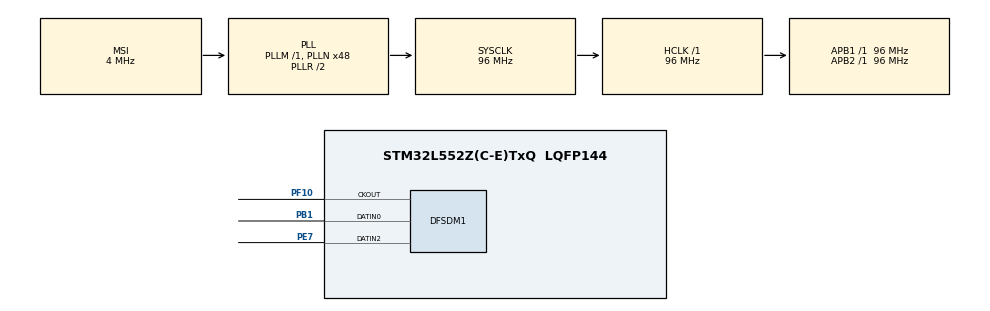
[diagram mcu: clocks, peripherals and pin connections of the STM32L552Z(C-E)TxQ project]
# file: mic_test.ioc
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DFSDM1.Divider=40
DFSDM1.DmaMode_reg_FIL0=ENABLE
DFSDM1.DmaMode_reg_FIL1=ENABLE
DFSDM1.DmaMode_reg_FIL2=ENABLE
DFSDM1.DmaMode_reg_FIL3=ENABLE
DFSDM1.FastMode_reg_FIL0=ENABLE
DFSDM1.FastMode_reg_FIL1=ENABLE
DFSDM1.FastMode_reg_FIL2=ENABLE
DFSDM1.FastMode_reg_FIL3=ENABLE
DFSDM1.Filter_regChannel_FIL0=DFSDM_CHANNEL_2
DFSDM1.Filter_regChannel_FIL1=DFSDM_CHANNEL_1
DFSDM1.Filter_regChannel_FIL2=DFSDM_CHANNEL_0
DFSDM1.Filter_regChannel_FIL3=DFSDM_CHANNEL_3
DFSDM1.Fosr_FIL0=150
DFSDM1.Fosr_FIL1=150
DFSDM1.Fosr_FIL2=150
DFSDM1.Fosr_FIL3=150
DFSDM1.RightBitShift_CH0=0x07
DFSDM1.RightBitShift_CH1=0x07
DFSDM1.RightBitShift_CH2=0x07
DFSDM1.RightBitShift_CH3=0x07
DFSDM1.SincOrder_FIL0=DFSDM_FILTER_SINC3_ORDER
DFSDM1.SincOrder_FIL1=DFSDM_FILTER_SINC3_ORDER
DFSDM1.SincOrder_FIL2=DFSDM_FILTER_SINC3_ORDER
DFSDM1.SincOrder_FIL3=DFSDM_FILTER_SINC3_ORDER
DFSDM1.Trigger_reg_FIL1=DFSDM_FILTER_SW_TRIGGER
DFSDM1.Trigger_reg_FIL2=DFSDM_FILTER_SW_TRIGGER
DFSDM1.Type_spi_CH1=DFSDM_CHANNEL_SPI_FALLING
DFSDM1.Type_spi_CH3=DFSDM_CHANNEL_SPI_FALLING
Dma.DFSDM1_FLT0.0.Channel_PRIV_NPRIV=DMA_CHANNEL_NPRIV_DISABLE
Dma.DFSDM1_FLT0.0.Direction=DMA_PERIPH_TO_MEMORY
Dma.DFSDM1_FLT0.0.EventEnable=DISABLE
Dma.DFSDM1_FLT0.0.Instance=DMA1_Channel1
Dma.DFSDM1_FLT0.0.MemDataAlignment=DMA_MDATAALIGN_WORD
Dma.DFSDM1_FLT0.0.MemInc=DMA_MINC_ENABLE
Dma.DFSDM1_FLT0.0.Mode=DMA_CIRCULAR
Dma.DFSDM1_FLT0.0.PeriphDataAlignment=DMA_PDATAALIGN_WORD
Dma.DFSDM1_FLT0.0.PeriphInc=DMA_PINC_DISABLE
Dma.DFSDM1_FLT0.0.Polarity=HAL_DMAMUX_REQ_GEN_RISING
Dma.DFSDM1_FLT0.0.Priority=DMA_PRIORITY_LOW
Dma.DFSDM1_FLT0.0.RequestNumber=1
Dma.DFSDM1_FLT0.0.SignalID=NONE
Dma.DFSDM1_FLT0.0.SyncEnable=DISABLE
Dma.DFSDM1_FLT0.0.SyncPolarity=HAL_DMAMUX_SYNC_NO_EVENT
Dma.DFSDM1_FLT0.0.SyncRequestNumber=1
Dma.DFSDM1_FLT0.0.SyncSignalID=NONE
Dma.DFSDM1_FLT1.1.Channel_PRIV_NPRIV=DMA_CHANNEL_NPRIV_DISABLE
Dma.DFSDM1_FLT1.1.Direction=DMA_PERIPH_TO_MEMORY
Dma.DFSDM1_FLT1.1.EventEnable=DISABLE
Dma.DFSDM1_FLT1.1.Instance=DMA1_Channel2
Dma.DFSDM1_FLT1.1.MemDataAlignment=DMA_MDATAALIGN_WORD
Dma.DFSDM1_FLT1.1.MemInc=DMA_MINC_ENABLE
Dma.DFSDM1_FLT1.1.Mode=DMA_CIRCULAR
Dma.DFSDM1_FLT1.1.PeriphDataAlignment=DMA_PDATAALIGN_WORD
Dma.DFSDM1_FLT1.1.PeriphInc=DMA_PINC_DISABLE
Dma.DFSDM1_FLT1.1.Polarity=HAL_DMAMUX_REQ_GEN_RISING
Dma.DFSDM1_FLT1.1.Priority=DMA_PRIORITY_LOW
Dma.DFSDM1_FLT1.1.RequestNumber=1
Dma.DFSDM1_FLT1.1.SignalID=NONE
Dma.DFSDM1_FLT1.1.SyncEnable=DISABLE
Dma.DFSDM1_FLT1.1.SyncPolarity=HAL_DMAMUX_SYNC_NO_EVENT
Dma.DFSDM1_FLT1.1.SyncRequestNumber=1
Dma.DFSDM1_FLT1.1.SyncSignalID=NONE
Dma.DFSDM1_FLT2.3.Channel_PRIV_NPRIV=DMA_CHANNEL_NPRIV_DISABLE
Dma.DFSDM1_FLT2.3.Direction=DMA_PERIPH_TO_MEMORY
Dma.DFSDM1_FLT2.3.EventEnable=DISABLE
Dma.DFSDM1_FLT2.3.Instance=DMA1_Channel4
Dma.DFSDM1_FLT2.3.MemDataAlignment=DMA_MDATAALIGN_WORD
Dma.DFSDM1_FLT2.3.MemInc=DMA_MINC_ENABLE
Dma.DFSDM1_FLT2.3.Mode=DMA_CIRCULAR
Dma.DFSDM1_FLT2.3.PeriphDataAlignment=DMA_PDATAALIGN_WORD
Dma.DFSDM1_FLT2.3.PeriphInc=DMA_PINC_DISABLE
Dma.DFSDM1_FLT2.3.Polarity=HAL_DMAMUX_REQ_GEN_RISING
Dma.DFSDM1_FLT2.3.Priority=DMA_PRIORITY_LOW
Dma.DFSDM1_FLT2.3.RequestNumber=1
Dma.DFSDM1_FLT2.3.SignalID=NONE
Dma.DFSDM1_FLT2.3.SyncEnable=DISABLE
Dma.DFSDM1_FLT2.3.SyncPolarity=HAL_DMAMUX_SYNC_NO_EVENT
Dma.DFSDM1_FLT2.3.SyncRequestNumber=1
Dma.DFSDM1_FLT2.3.SyncSignalID=NONE
Dma.DFSDM1_FLT3.2.Channel_PRIV_NPRIV=DMA_CHANNEL_NPRIV_DISABLE
Dma.DFSDM1_FLT3.2.Direction=DMA_PERIPH_TO_MEMORY
Dma.DFSDM1_FLT3.2.EventEnable=DISABLE
Dma.DFSDM1_FLT3.2.Instance=DMA1_Channel3
Dma.DFSDM1_FLT3.2.MemDataAlignment=DMA_MDATAALIGN_WORD
Dma.DFSDM1_FLT3.2.MemInc=DMA_MINC_ENABLE
Dma.DFSDM1_FLT3.2.Mode=DMA_CIRCULAR
Dma.DFSDM1_FLT3.2.PeriphDataAlignment=DMA_PDATAALIGN_WORD
Dma.DFSDM1_FLT3.2.PeriphInc=DMA_PINC_DISABLE
Dma.DFSDM1_FLT3.2.Polarity=HAL_DMAMUX_REQ_GEN_RISING
Dma.DFSDM1_FLT3.2.Priority=DMA_PRIORITY_LOW
Dma.DFSDM1_FLT3.2.RequestNumber=1
Dma.DFSDM1_FLT3.2.SignalID=NONE
Dma.DFSDM1_FLT3.2.SyncEnable=DISABLE
Dma.DFSDM1_FLT3.2.SyncPolarity=HAL_DMAMUX_SYNC_NO_EVENT
Dma.DFSDM1_FLT3.2.SyncRequestNumber=1
Dma.DFSDM1_FLT3.2.SyncSignalID=NONE
Dma.Request0=DFSDM1_FLT0
Dma.Request1=DFSDM1_FLT1
Dma.Request2=DFSDM1_FLT3
Dma.Request3=DFSDM1_FLT2
Mcu.Family=STM32L5
Mcu.Name=STM32L552Z(C-E)TxQ
Mcu.Package=LQFP144
Mcu.TrustZone=disable
NUCLEO-L552ZE-Q.BUTTON=1
NUCLEO-L552ZE-Q.Bsp_Common_DEMO=true
NUCLEO-L552ZE-Q.LD1=true
NUCLEO-L552ZE-Q.LD2=true
NUCLEO-L552ZE-Q.LD3=true
NUCLEO-L552ZE-Q.VCP=true
NVIC.DMA1_Channel1_IRQn=true\:0\:0\:false\:false\:true\:false\:true\:true
NVIC.DMA1_Channel2_IRQn=true\:0\:0\:false\:false\:true\:false\:true\:true
NVIC.DMA1_Channel3_IRQn=true\:0\:0\:false\:false\:true\:false\:true\:true
NVIC.DMA1_Channel4_IRQn=true\:0\:0\:false\:false\:true\:false\:true\:true
NVIC.EXTI13_IRQn=true\:0\:0\:false\:false\:true\:false\:true\:true
NVIC.PriorityGroup=NVIC_PRIORITYGROUP_3
PA13\ (JTMS/SWDIO).Signal=DEBUG_JTMS-SWDIO
PA14\ (JTCK/SWCLK).Signal=DEBUG_JTCK-SWCLK
PB1.Signal=S_DATAIN0DFSDM1
PB3\ (JTDO/TRACESWO).Signal=DEBUG_JTDO-SWO
PC14-OSC32_IN\ (PC14).Signal=RCC_OSC32_IN
PC15-OSC32_OUT\ (PC15).Signal=RCC_OSC32_OUT
PE7.Signal=S_DATAIN2DFSDM1
PF10.Signal=S_CKOUTDFSDM1
PG7.Signal=LPUART1_TX
PG8.Signal=LPUART1_RX
ProjectManager.HeapSize=0x200
ProjectManager.StackSize=0x400
ProjectManager.TargetToolchain=STM32CubeIDE
RCC.ADCCLockSelection=RCC_ADCCLKSOURCE_SYSCLK
RCC.ADCFreq_Value=96000000
RCC.AHBFreq_Value=96000000
RCC.APB1Freq_Value=96000000
RCC.APB1TimFreq_Value=96000000
RCC.APB2Freq_Value=96000000
RCC.APB2TimFreq_Value=96000000
RCC.CK48CLockSelection=RCC_USBCLKSOURCE_HSI48
RCC.CortexFreq_Value=96000000
RCC.HCLKFreq_Value=96000000
RCC.HSE_VALUE=8000000
RCC.HSI48_VALUE=48000000
RCC.HSI_VALUE=16000000
RCC.LSE_VALUE=32768
RCC.MSI_VALUE=4000000
RCC.PLLN=48
RCC.PLLSAI1N=24
RCC.RTCClockSelection=RCC_RTCCLKSOURCE_LSE
RCC.SYSCLKFreq_VALUE=96000000
RCC.SYSCLKSource=RCC_SYSCLKSOURCE_PLLCLK
RCC.USBFreq_Value=48000000
RCC.VCOOutputFreq_Value=192000000
SH.S_CKOUTDFSDM1.0=DFSDM1_CKOUT,PDM_SPI_input_from_ch2_and_internal_clock
SH.S_CKOUTDFSDM1.1=DFSDM1_CKOUT,PDM_SPI_Input_from_ch12_and_Internal_Clock
SH.S_CKOUTDFSDM1.2=DFSDM1_CKOUT,PDM_SPI_input_from_ch0_and_internal_clock
SH.S_CKOUTDFSDM1.3=DFSDM1_CKOUT,PDM_SPI_Input_from_ch30_and_Internal_Clock
SH.S_DATAIN0DFSDM1.0=DFSDM1_DATIN0,PDM_SPI_input_from_ch0_and_internal_clock
SH.S_DATAIN0DFSDM1.1=DFSDM1_DATIN0,PDM_SPI_Input_from_ch30_and_Internal_Clock
SH.S_DATAIN2DFSDM1.0=DFSDM1_DATIN2,PDM_SPI_input_from_ch2_and_internal_clock
SH.S_DATAIN2DFSDM1.1=DFSDM1_DATIN2,PDM_SPI_Input_from_ch12_and_Internal_Clock
VP_ICACHE_VS_ICACHE.Mode=DirectMappedCache
VP_NUCLEO-L552ZE-Q_VS_BSP_COMMON.Mode=COMMON
VP_PWR_VS_DBSignals.Mode=DisableDeadBatterySignals
VP_PWR_VS_SECSignals.Mode=Security/Privilege
board=NUCLEO-L552ZE-Q

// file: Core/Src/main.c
/* USER CODE BEGIN Header */
/**
  ******************************************************************************
  * @file           : main.c
  * @brief          : Main program body
  ******************************************************************************
  * @attention
  *
  * Copyright (c) 2026 STMicroelectronics.
  * All rights reserved.
  *
  * This software is licensed under terms that can be found in the LICENSE file
  * in the root directory of this software component.
  * If no LICENSE file comes with this software, it is provided AS-IS.
  *
  ******************************************************************************
  */
/* USER CODE END Header */
#include "main.h"

/* USER CODE BEGIN Includes */
#include "capture.h"
#include "localize.h"
/* USER CODE END Includes */

/* USER CODE BEGIN PD */
/* Capture configuration and buffers now live in capture.c / capture.h. */
/* USER CODE END PD */

COM_InitTypeDef BspCOMInit;
__IO uint32_t BspButtonState = BUTTON_RELEASED;
DFSDM_Filter_HandleTypeDef hdfsdm1_filter0;
DFSDM_Filter_HandleTypeDef hdfsdm1_filter1;
DFSDM_Filter_HandleTypeDef hdfsdm1_filter2;
DFSDM_Filter_HandleTypeDef hdfsdm1_filter3;
DFSDM_Channel_HandleTypeDef hdfsdm1_channel0;
DFSDM_Channel_HandleTypeDef hdfsdm1_channel1;
DFSDM_Channel_HandleTypeDef hdfsdm1_channel2;
DFSDM_Channel_HandleTypeDef hdfsdm1_channel3;
DMA_HandleTypeDef hdma_dfsdm1_flt0;
DMA_HandleTypeDef hdma_dfsdm1_flt1;
DMA_HandleTypeDef hdma_dfsdm1_flt3;
DMA_HandleTypeDef hdma_dfsdm1_flt2;

/* USER CODE BEGIN PV */
/* Capture buffers and state now live in capture.c (file-private). */
/* USER CODE END PV */

void SystemClock_Config(void);
static void MX_GPIO_Init(void);
static void MX_DMA_Init(void);
static void MX_ICACHE_Init(void);
static void MX_DFSDM1_Init(void);

/* USER CODE BEGIN 0 */
/* Capture helpers, DMA callbacks, and state machine now live in capture.c. */
/* USER CODE END 0 */

int main(void)
{

  /* MCU Configuration--------------------------------------------------------*/

  /* Reset of all peripherals, Initializes the Flash interface and the Systick. */
  HAL_Init();

  /* Configure the system clock */
  SystemClock_Config();

  /* Initialize all configured peripherals */
  MX_GPIO_Init();
  MX_DMA_Init();
  MX_ICACHE_Init();
  MX_DFSDM1_Init();
  /* USER CODE BEGIN 2 */

  /* Force filters 1-3 onto the sync trigger so they start in lockstep when
     filter0 starts. CubeMX generates SW_TRIGGER for all four; re-init the
     three slaves here so this holds even after a future regeneration. */
  hdfsdm1_filter1.Init.RegularParam.Trigger = DFSDM_FILTER_SYNC_TRIGGER;
  hdfsdm1_filter2.Init.RegularParam.Trigger = DFSDM_FILTER_SYNC_TRIGGER;
  hdfsdm1_filter3.Init.RegularParam.Trigger = DFSDM_FILTER_SYNC_TRIGGER;
  if (HAL_DFSDM_FilterInit(&hdfsdm1_filter1) != HAL_OK) Error_Handler();
  if (HAL_DFSDM_FilterInit(&hdfsdm1_filter2) != HAL_OK) Error_Handler();
  if (HAL_DFSDM_FilterInit(&hdfsdm1_filter3) != HAL_OK) Error_Handler();

  /* USER CODE END 2 */

  /* Initialize leds */
  BSP_LED_Init(LED_GREEN);
  BSP_LED_Init(LED_BLUE);
  BSP_LED_Init(LED_RED);

  /* Initialize USER push-button, will be used to trigger an interrupt each time it's pressed.*/
  BSP_PB_Init(BUTTON_USER, BUTTON_MODE_EXTI);

  /* Initialize COM1 port (115200, 8 bits (7-bit data + 1 stop bit), no parity */
  BspCOMInit.BaudRate   = 115200;
  BspCOMInit.WordLength = COM_WORDLENGTH_8B;
  BspCOMInit.StopBits   = COM_STOPBITS_1;
  BspCOMInit.Parity     = COM_PARITY_NONE;
  BspCOMInit.HwFlowCtl  = COM_HWCONTROL_NONE;
  if (BSP_COM_Init(COM1, &BspCOMInit) != BSP_ERROR_NONE)
  {
    Error_Handler();
  }

  /* USER CODE BEGIN BSP */

  /* -- Sample board code to send message over COM1 port ---- */
  printf("Welcome to STM32 world !\n\r");

  /* Prepare the on-board localizer: sets up the FFT and validates the active
     array geometry. Done once here rather than lazily on the first capture so
     a bad configuration is reported at boot, not eleven seconds after a clap. */
  if (!Localize_Init())
  {
    printf("WARNING: localizer failed to initialise. Captures will still be "
           "dumped, but no bearing will be computed.\r\n");
  }

  /* USER CODE END BSP */

  /* Infinite loop */
  /* USER CODE BEGIN WHILE */
  while (1)
  {
    /* IDLE: watch for the button. BspButtonState is set to BUTTON_PRESSED by
       the button's own interrupt (EXTI13 -> BSP_PB_Callback). A press arms a
       capture; Capture_Arm ignores it if one is already running. */
    if (BspButtonState == BUTTON_PRESSED)
    {
      BspButtonState = BUTTON_RELEASED;   /* consume the press so it fires once */
      Capture_Arm();
    }

    /* Run the capture state machine: drain the DMA frames, watch for the
       clap, and once a full second is banked, dump it over UART. Does
       nothing until armed. See capture.c. */
    Capture_Poll();

    /* A capture just finished and its raw audio is already on the wire.
       Localize it and print the bearing after the dump, so catch_audio4.py
       gets a clean WAV4 payload and the report lands in the terminal behind
       it. Takes a few tens of milliseconds; nothing else is time critical
       here because the array is idle until the next button press. */
    if (Capture_TakeResult())
    {
      static const int16_t *chans[4];
      for (int m = 0; m < 4; m++) chans[m] = Capture_Channel(m);

      static loc_result_t result;
      Localize_Run(chans, Capture_Length(), &result);
      Localize_Report(&result);
    }
    /* USER CODE END WHILE */

  }
}

void SystemClock_Config(void)
{
  RCC_OscInitTypeDef RCC_OscInitStruct = {0};
  RCC_ClkInitTypeDef RCC_ClkInitStruct = {0};

  /** Configure the main internal regulator output voltage
  */
  if (HAL_PWREx_ControlVoltageScaling(PWR_REGULATOR_VOLTAGE_SCALE0) != HAL_OK)
  {
    Error_Handler();
  }

  /** Initializes the RCC Oscillators according to the specified parameters
  * in the RCC_OscInitTypeDef structure.
  */
  RCC_OscInitStruct.OscillatorType = RCC_OSCILLATORTYPE_MSI;
  RCC_OscInitStruct.MSIState = RCC_MSI_ON;
  RCC_OscInitStruct.MSICalibrationValue = RCC_MSICALIBRATION_DEFAULT;
  RCC_OscInitStruct.MSIClockRange = RCC_MSIRANGE_6;
  RCC_OscInitStruct.PLL.PLLState = RCC_PLL_ON;
  RCC_OscInitStruct.PLL.PLLSource = RCC_PLLSOURCE_MSI;
  RCC_OscInitStruct.PLL.PLLM = 1;
  RCC_OscInitStruct.PLL.PLLN = 48;
  RCC_OscInitStruct.PLL.PLLP = RCC_PLLP_DIV7;
  RCC_OscInitStruct.PLL.PLLQ = RCC_PLLQ_DIV2;
  RCC_OscInitStruct.PLL.PLLR = RCC_PLLR_DIV2;
  if (HAL_RCC_OscConfig(&RCC_OscInitStruct) != HAL_OK)
  {
    Error_Handler();
  }

  /** Initializes the CPU, AHB and APB buses clocks
  */
  RCC_ClkInitStruct.ClockType = RCC_CLOCKTYPE_HCLK|RCC_CLOCKTYPE_SYSCLK
                              |RCC_CLOCKTYPE_PCLK1|RCC_CLOCKTYPE_PCLK2;
  RCC_ClkInitStruct.SYSCLKSource = RCC_SYSCLKSOURCE_PLLCLK;
  RCC_ClkInitStruct.AHBCLKDivider = RCC_SYSCLK_DIV1;
  RCC_ClkInitStruct.APB1CLKDivider = RCC_HCLK_DIV1;
  RCC_ClkInitStruct.APB2CLKDivider = RCC_HCLK_DIV1;

  if (HAL_RCC_ClockConfig(&RCC_ClkInitStruct, FLASH_LATENCY_4) != HAL_OK)
  {
    Error_Handler();
  }
}

static void MX_DFSDM1_Init(void)
{

  hdfsdm1_filter0.Instance = DFSDM1_Filter0;
  hdfsdm1_filter0.Init.RegularParam.Trigger = DFSDM_FILTER_SW_TRIGGER;
  hdfsdm1_filter0.Init.RegularParam.FastMode = ENABLE;
  hdfsdm1_filter0.Init.RegularParam.DmaMode = ENABLE;
  hdfsdm1_filter0.Init.FilterParam.SincOrder = DFSDM_FILTER_SINC3_ORDER;
  hdfsdm1_filter0.Init.FilterParam.Oversampling = 150;
  hdfsdm1_filter0.Init.FilterParam.IntOversampling = 1;
  if (HAL_DFSDM_FilterInit(&hdfsdm1_filter0) != HAL_OK)
  {
    Error_Handler();
  }
  hdfsdm1_filter1.Instance = DFSDM1_Filter1;
  hdfsdm1_filter1.Init.RegularParam.Trigger = DFSDM_FILTER_SW_TRIGGER;
  hdfsdm1_filter1.Init.RegularParam.FastMode = ENABLE;
  hdfsdm1_filter1.Init.RegularParam.DmaMode = ENABLE;
  hdfsdm1_filter1.Init.FilterParam.SincOrder = DFSDM_FILTER_SINC3_ORDER;
  hdfsdm1_filter1.Init.FilterParam.Oversampling = 150;
  hdfsdm1_filter1.Init.FilterParam.IntOversampling = 1;
  if (HAL_DFSDM_FilterInit(&hdfsdm1_filter1) != HAL_OK)
  {
    Error_Handler();
  }
  hdfsdm1_filter2.Instance = DFSDM1_Filter2;
  hdfsdm1_filter2.Init.RegularParam.Trigger = DFSDM_FILTER_SW_TRIGGER;
  hdfsdm1_filter2.Init.RegularParam.FastMode = ENABLE;
  hdfsdm1_filter2.Init.RegularParam.DmaMode = ENABLE;
  hdfsdm1_filter2.Init.FilterParam.SincOrder = DFSDM_FILTER_SINC3_ORDER;
  hdfsdm1_filter2.Init.FilterParam.Oversampling = 150;
  hdfsdm1_filter2.Init.FilterParam.IntOversampling = 1;
  if (HAL_DFSDM_FilterInit(&hdfsdm1_filter2) != HAL_OK)
  {
    Error_Handler();
  }
  hdfsdm1_filter3.Instance = DFSDM1_Filter3;
  hdfsdm1_filter3.Init.RegularParam.Trigger = DFSDM_FILTER_SW_TRIGGER;
  hdfsdm1_filter3.Init.RegularParam.FastMode = ENABLE;
  hdfsdm1_filter3.Init.RegularParam.DmaMode = ENABLE;
  hdfsdm1_filter3.Init.FilterParam.SincOrder = DFSDM_FILTER_SINC3_ORDER;
  hdfsdm1_filter3.Init.FilterParam.Oversampling = 150;
  hdfsdm1_filter3.Init.FilterParam.IntOversampling = 1;
  if (HAL_DFSDM_FilterInit(&hdfsdm1_filter3) != HAL_OK)
  {
    Error_Handler();
  }
  hdfsdm1_channel0.Instance = DFSDM1_Channel0;
  hdfsdm1_channel0.Init.OutputClock.Activation = ENABLE;
  hdfsdm1_channel0.Init.OutputClock.Selection = DFSDM_CHANNEL_OUTPUT_CLOCK_SYSTEM;
  hdfsdm1_channel0.Init.OutputClock.Divider = 40;
  hdfsdm1_channel0.Init.Input.Multiplexer = DFSDM_CHANNEL_EXTERNAL_INPUTS;
  hdfsdm1_channel0.Init.Input.DataPacking = DFSDM_CHANNEL_STANDARD_MODE;
  hdfsdm1_channel0.Init.Input.Pins = DFSDM_CHANNEL_SAME_CHANNEL_PINS;
  hdfsdm1_channel0.Init.SerialInterface.Type = DFSDM_CHANNEL_SPI_RISING;
  hdfsdm1_channel0.Init.SerialInterface.SpiClock = DFSDM_CHANNEL_SPI_CLOCK_INTERNAL;
  hdfsdm1_channel0.Init.Awd.FilterOrder = DFSDM_CHANNEL_FASTSINC_ORDER;
  hdfsdm1_channel0.Init.Awd.Oversampling = 1;
  hdfsdm1_channel0.Init.Offset = 0;
  hdfsdm1_channel0.Init.RightBitShift = 0x07;
  if (HAL_DFSDM_ChannelInit(&hdfsdm1_channel0) != HAL_OK)
  {
    Error_Handler();
  }
  hdfsdm1_channel1.Instance = DFSDM1_Channel1;
  hdfsdm1_channel1.Init.OutputClock.Activation = ENABLE;
  hdfsdm1_channel1.Init.OutputClock.Selection = DFSDM_CHANNEL_OUTPUT_CLOCK_SYSTEM;
  hdfsdm1_channel1.Init.OutputClock.Divider = 40;
  hdfsdm1_channel1.Init.Input.Multiplexer = DFSDM_CHANNEL_EXTERNAL_INPUTS;
  hdfsdm1_channel1.Init.Input.DataPacking = DFSDM_CHANNEL_STANDARD_MODE;
  hdfsdm1_channel1.Init.Input.Pins = DFSDM_CHANNEL_FOLLOWING_CHANNEL_PINS;
  hdfsdm1_channel1.Init.SerialInterface.Type = DFSDM_CHANNEL_SPI_FALLING;
  hdfsdm1_channel1.Init.SerialInterface.SpiClock = DFSDM_CHANNEL_SPI_CLOCK_INTERNAL;
  hdfsdm1_channel1.Init.Awd.FilterOrder = DFSDM_CHANNEL_FASTSINC_ORDER;
  hdfsdm1_channel1.Init.Awd.Oversampling = 1;
  hdfsdm1_channel1.Init.Offset = 0;
  hdfsdm1_channel1.Init.RightBitShift = 0x07;
  if (HAL_DFSDM_ChannelInit(&hdfsdm1_channel1) != HAL_OK)
  {
    Error_Handler();
  }
  hdfsdm1_channel2.Instance = DFSDM1_Channel2;
  hdfsdm1_channel2.Init.OutputClock.Activation = ENABLE;
  hdfsdm1_channel2.Init.OutputClock.Selection = DFSDM_CHANNEL_OUTPUT_CLOCK_SYSTEM;
  hdfsdm1_channel2.Init.OutputClock.Divider = 40;
  hdfsdm1_channel2.Init.Input.Multiplexer = DFSDM_CHANNEL_EXTERNAL_INPUTS;
  hdfsdm1_channel2.Init.Input.DataPacking = DFSDM_CHANNEL_STANDARD_MODE;
  hdfsdm1_channel2.Init.Input.Pins = DFSDM_CHANNEL_SAME_CHANNEL_PINS;
  hdfsdm1_channel2.Init.SerialInterface.Type = DFSDM_CHANNEL_SPI_RISING;
  hdfsdm1_channel2.Init.SerialInterface.SpiClock = DFSDM_CHANNEL_SPI_CLOCK_INTERNAL;
  hdfsdm1_channel2.Init.Awd.FilterOrder = DFSDM_CHANNEL_FASTSINC_ORDER;
  hdfsdm1_channel2.Init.Awd.Oversampling = 1;
  hdfsdm1_channel2.Init.Offset = 0;
  hdfsdm1_channel2.Init.RightBitShift = 0x07;
  if (HAL_DFSDM_ChannelInit(&hdfsdm1_channel2) != HAL_OK)
  {
    Error_Handler();
  }
  hdfsdm1_channel3.Instance = DFSDM1_Channel3;
  hdfsdm1_channel3.Init.OutputClock.Activation = ENABLE;
  hdfsdm1_channel3.Init.OutputClock.Selection = DFSDM_CHANNEL_OUTPUT_CLOCK_SYSTEM;
  hdfsdm1_channel3.Init.OutputClock.Divider = 40;
  hdfsdm1_channel3.Init.Input.Multiplexer = DFSDM_CHANNEL_EXTERNAL_INPUTS;
  hdfsdm1_channel3.Init.Input.DataPacking = DFSDM_CHANNEL_STANDARD_MODE;
  hdfsdm1_channel3.Init.Input.Pins = DFSDM_CHANNEL_FOLLOWING_CHANNEL_PINS;
  hdfsdm1_channel3.Init.SerialInterface.Type = DFSDM_CHANNEL_SPI_FALLING;
  hdfsdm1_channel3.Init.SerialInterface.SpiClock = DFSDM_CHANNEL_SPI_CLOCK_INTERNAL;
  hdfsdm1_channel3.Init.Awd.FilterOrder = DFSDM_CHANNEL_FASTSINC_ORDER;
  hdfsdm1_channel3.Init.Awd.Oversampling = 1;
  hdfsdm1_channel3.Init.Offset = 0;
  hdfsdm1_channel3.Init.RightBitShift = 0x07;
  if (HAL_DFSDM_ChannelInit(&hdfsdm1_channel3) != HAL_OK)
  {
    Error_Handler();
  }
  if (HAL_DFSDM_FilterConfigRegChannel(&hdfsdm1_filter0, DFSDM_CHANNEL_2, DFSDM_CONTINUOUS_CONV_ON) != HAL_OK)
  {
    Error_Handler();
  }
  if (HAL_DFSDM_FilterConfigRegChannel(&hdfsdm1_filter1, DFSDM_CHANNEL_1, DFSDM_CONTINUOUS_CONV_ON) != HAL_OK)
  {
    Error_Handler();
  }
  if (HAL_DFSDM_FilterConfigRegChannel(&hdfsdm1_filter2, DFSDM_CHANNEL_0, DFSDM_CONTINUOUS_CONV_ON) != HAL_OK)
  {
    Error_Handler();
  }
  if (HAL_DFSDM_FilterConfigRegChannel(&hdfsdm1_filter3, DFSDM_CHANNEL_3, DFSDM_CONTINUOUS_CONV_ON) != HAL_OK)
  {
    Error_Handler();
  }

}

static void MX_ICACHE_Init(void)
{

  /** Enable instruction cache in 1-way (direct mapped cache)
  */
  if (HAL_ICACHE_ConfigAssociativityMode(ICACHE_1WAY) != HAL_OK)
  {
    Error_Handler();
  }
  if (HAL_ICACHE_Enable() != HAL_OK)
  {
    Error_Handler();
  }

}

static void MX_DMA_Init(void)
{

  /* DMA controller clock enable */
  __HAL_RCC_DMAMUX1_CLK_ENABLE();
  __HAL_RCC_DMA1_CLK_ENABLE();

  /* DMA interrupt init */
  /* DMA1_Channel1_IRQn interrupt configuration */
  HAL_NVIC_SetPriority(DMA1_Channel1_IRQn, 0, 0);
  HAL_NVIC_EnableIRQ(DMA1_Channel1_IRQn);
  /* DMA1_Channel2_IRQn interrupt configuration */
  HAL_NVIC_SetPriority(DMA1_Channel2_IRQn, 0, 0);
  HAL_NVIC_EnableIRQ(DMA1_Channel2_IRQn);
  /* DMA1_Channel3_IRQn interrupt configuration */
  HAL_NVIC_SetPriority(DMA1_Channel3_IRQn, 0, 0);
  HAL_NVIC_EnableIRQ(DMA1_Channel3_IRQn);
  /* DMA1_Channel4_IRQn interrupt configuration */
  HAL_NVIC_SetPriority(DMA1_Channel4_IRQn, 0, 0);
  HAL_NVIC_EnableIRQ(DMA1_Channel4_IRQn);

}

static void MX_GPIO_Init(void)
{

  /* GPIO Ports Clock Enable */
  __HAL_RCC_GPIOC_CLK_ENABLE();
  __HAL_RCC_GPIOF_CLK_ENABLE();
  __HAL_RCC_GPIOB_CLK_ENABLE();
  __HAL_RCC_GPIOE_CLK_ENABLE();
  __HAL_RCC_GPIOA_CLK_ENABLE();

}

/* USER CODE BEGIN 4 */
/* The DFSDM DMA callbacks now live in capture.c (they override the HAL weak
   defaults from there just the same). */
/* USER CODE END 4 */

/**
  * @brief BSP Push Button callback
  * @param Button Specifies the pressed button
  * @retval None
  */
void BSP_PB_Callback(Button_TypeDef Button)
{
  if (Button == BUTTON_USER)
  {
    BspButtonState = BUTTON_PRESSED;
  }
}

void Error_Handler(void)
{
  __disable_irq();
  while (1)
  {
  }
}
